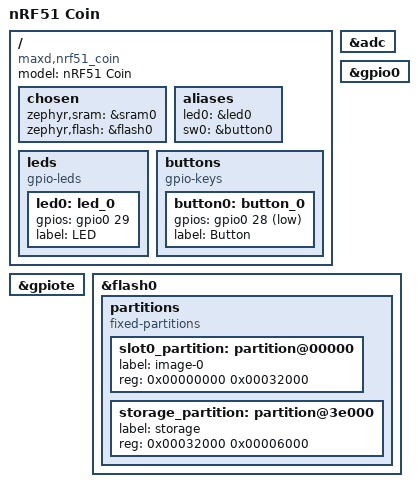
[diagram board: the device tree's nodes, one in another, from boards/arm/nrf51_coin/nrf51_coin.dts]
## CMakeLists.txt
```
cmake_minimum_required(VERSION 3.8.2)

get_filename_component( ENV{ZEPHYR_BASE} "${CMAKE_SOURCE_DIR}/../zephyr" ABSOLUTE)
set( ENV{BOARD} nrf51_coin )
set( BOARD_ROOT ${CMAKE_SOURCE_DIR} )
set( ENV{ZEPHYR_TOOLCHAIN_VARIANT} zephyr )
set( ENV{ZEPHYR_SDK_INSTALL_DIR} /opt/zephyr-sdk/ )

include($ENV{ZEPHYR_BASE}/cmake/app/boilerplate.cmake NO_POLICY_SCOPE)

project(coin)
zephyr_include_directories(
  $ENV{ZEPHYR_BASE}/subsys/bluetooth/host
  ../BLAKE2/ref
)


target_sources(app PRIVATE src/main.c src/bas.c src/io.c src/spaceauth.c ../BLAKE2/ref/blake2s-ref.c)
```

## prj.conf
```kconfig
CONFIG_BT=y
CONFIG_BT_SMP=y
CONFIG_BT_PERIPHERAL=y

CONFIG_BT_PRIVACY=y

CONFIG_BT_SMP_SC_ONLY=y
CONFIG_BT_MAX_CONN=1
CONFIG_BT_MAX_PAIRED=1

CONFIG_BT_SETTINGS=y
CONFIG_BT_BONDABLE=n
CONFIG_BT_DEVICE_NAME="Space"
CONFIG_BT_DEVICE_APPEARANCE=576
CONFIG_FLASH=y
CONFIG_FLASH_PAGE_LAYOUT=y
CONFIG_FLASH_MAP=y
CONFIG_FCB=y
CONFIG_SETTINGS=y
CONFIG_SETTINGS_FCB=y

CONFIG_SYS_POWER_MANAGEMENT=y
CONFIG_SYS_POWER_DEEP_SLEEP_STATES=y
CONFIG_DEVICE_POWER_MANAGEMENT=y
CONFIG_ADC=y
CONFIG_ADC_0=y

CONFIG_BT_LL_SW_LEGACY=y

# "advanced settings"
#CONFIG_BT_HCI_TX_STACK_SIZE=640
#CONFIG_BT_HCI_ECC_STACK_SIZE=1100
#CONFIG_BT_RX_STACK_SIZE=2200
#CONFIG_BT_CTLR_RX_PRIO_STACK_SIZE=448
#CONFIG_ISR_STACK_SIZE=640
CONFIG_MAIN_STACK_SIZE=512
#CONFIG_IDLE_STACK_SIZE=256
CONFIG_SYSTEM_WORKQUEUE_STACK_SIZE=512
CONFIG_OFFLOAD_WORKQUEUE_STACK_SIZE=512
CONFIG_BT_HCI_VS=n
CONFIG_BT_ASSERT=n
CONFIG_BT_RX_BUF_COUNT=2
CONFIG_BT_CONN_TX_MAX=1
CONFIG_BT_DISCARDABLE_BUF_COUNT=1
CONFIG_BT_L2CAP_TX_BUF_COUNT=2
#CONFIG_BT_ATT_TX_MAX=1
CONFIG_BT_GATT_READ_MULTIPLE=n
#CONFIG_BT_GAP_PERIPHERAL_PREF_PARAMS=n
#CONFIG_BT_CTLR_TX_BUFFERS=1
```

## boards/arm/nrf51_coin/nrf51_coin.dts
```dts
/*
 * Copyright (c) Maximilian Deubel
 *
 * SPDX-License-Identifier: Apache-2.0
 */

/dts-v1/;
#include <nordic/nrf51822_qfaa.dtsi>

/ {
	model = "nRF51 Coin";
	compatible = "maxd,nrf51_coin", "nordic,nrf51822-qfaa",
		     "nordic,nrf51822";

	chosen {
		zephyr,sram = &sram0;
		zephyr,flash = &flash0;
	};

	aliases {
		led0 = &led0;
		sw0 = &button0;
	};

	leds {
		compatible = "gpio-leds";
		led0: led_0 {
			gpios = <&gpio0 29 0>;
			label = "LED";
		};
	};

	buttons {
		compatible = "gpio-keys";
		button0: button_0 {
			gpios = <&gpio0 28 (GPIO_PUD_PULL_UP |
					    GPIO_INT_ACTIVE_LOW)>;
			label = "Button";
		};
	};
};

&adc {
	status ="okay";
};

&gpiote {
	status ="okay";
};

&gpio0 {
	status ="okay";
};

&flash0 {
	/*
	 * For more information, see:
	 * http://docs.zephyrproject.org/latest/guides/dts/index.html#flash-partitions
	 */
	partitions {
		compatible = "fixed-partitions";
		#address-cells = <1>;
		#size-cells = <1>;

		slot0_partition: partition@00000 {
			label = "image-0";
			reg = <0x00000000 0x00032000>;
		};
		storage_partition: partition@3e000 {
			label = "storage";
			reg = <0x00032000 0x00006000>;
		};
		/*
		 * REMEMBER TO UPDATE ADDRESS AND LENGTH IN prod/gen_bond.py
		 */
	};
};
```

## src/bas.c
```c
#include <zephyr.h>

uint8_t bas_init() {
	return 0;
}
```

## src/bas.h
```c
#pragma once

#ifdef __cplusplus
extern "C" {
#endif

/**
 * Initialize Battery Service.
 * This implementation directly uses the ADC with the on-board resistor divider to measure battery level.
 * @return initially measured battery level
 */
uint8_t bas_init();

#ifdef __cplusplus
}
#endif
```

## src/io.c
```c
#include "io.h"
#include <gpio.h>
#include <power.h>

#include <logging/log.h>

LOG_MODULE_REGISTER(io);

#define LED_PORT DT_ALIAS_LED0_GPIOS_CONTROLLER
#define LED DT_ALIAS_LED0_GPIOS_PIN
#define BTN DT_ALIAS_SW0_GPIOS_PIN

static struct gpio_callback btn_cb = {{0}};

static struct device *dev = NULL;

struct k_timer blink_timer = {{{{0}}}};

static const int aggressive_blink_ms = 125;
static const int quick_blink_ms = 250;
static const int slow_blink_ms = 500;

static const uint16_t sos_sequence[] = {250, 125, 250, 125, 250, 125,
                                        500, 125, 500, 125, 500, 125,
                                        250, 125, 250, 125, 250, 1000,
                                        250, 125, 250, 125, 250, 125,
                                        500, 125, 500, 125, 500, 125,
                                        250, 125, 250, 125, 250, 125};
static int sos_index = -1;

void set_blink_intensity(blink_state_t intensity) {
    if (sos_index > -1) {
        return;
    }
    switch (intensity) {
        case BI_ON:
            LOG_INF("turn LED on");
            k_timer_stop(&blink_timer);
            gpio_pin_write(dev, LED, 1);
            break;
        case BI_AGGRESSIVE:
            LOG_INF("aggressive LED blink");
            k_timer_start(&blink_timer, K_MSEC(aggressive_blink_ms), K_MSEC(aggressive_blink_ms));
            break;
        case BI_QUICK:
            LOG_INF("quick LED blink");
            k_timer_start(&blink_timer, K_MSEC(quick_blink_ms), K_MSEC(quick_blink_ms));
            break;
        case BI_SLOW:
            LOG_INF("slow LED blink");
            k_timer_start(&blink_timer, K_MSEC(slow_blink_ms), K_MSEC(slow_blink_ms));
            break;
        case BI_SOS:
            LOG_INF("distress signal");
            gpio_pin_write(dev, LED, 1);
            sos_index = 0;
            k_timer_start(&blink_timer, K_MSEC(sos_sequence[0]), 0);
            break;
        default:
        case BI_OFF:
            LOG_INF("turn LED off");
            k_timer_stop(&blink_timer);
            gpio_pin_write(dev, LED, 0);
            break;
    }
}

static int blink_counter = 0;

static void blink_expiry_function(struct k_timer *timer_id) {
    ARG_UNUSED(timer_id);
    if (sos_index > -1) { //SOS mode
        sos_index += 1;
        if (sos_index < ARRAY_SIZE(sos_sequence)) {
            gpio_pin_write(dev, LED, 1 - (sos_index % 2));
            k_timer_start(&blink_timer, K_MSEC(sos_sequence[sos_index]), 0);
        } else {
            gpio_pin_write(dev, LED, 0);
            sys_pm_force_power_state(SYS_POWER_STATE_DEEP_SLEEP_1);
        }
    } else {
        gpio_pin_write(dev, LED, (blink_counter++) % 2);
    }
}

static void button_pressed(struct device *btn_dev, struct gpio_callback *cb, u32_t pins) {
    ARG_UNUSED(btn_dev);
    ARG_UNUSED(cb);
    ARG_UNUSED(pins);
    //LOG_INF("button pressed");
}

void io_init() {
    LOG_INF("initialize LED and button");
    dev = device_get_binding(LED_PORT);

    gpio_pin_configure(dev, LED, GPIO_DIR_OUT);
    gpio_pin_configure(dev, BTN,
                       GPIO_DIR_IN | GPIO_PUD_PULL_UP | GPIO_INT_LEVEL |
                       GPIO_INT | GPIO_INT_ACTIVE_LOW);
    gpio_init_callback(&btn_cb, button_pressed, BIT(BTN));
    gpio_add_callback(dev, &btn_cb);
    gpio_pin_enable_callback(dev, BTN);

    k_timer_init(&blink_timer, blink_expiry_function, NULL);
    set_blink_intensity(BI_ON);
}
```

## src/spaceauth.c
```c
#include <zephyr.h>
#include <settings/settings.h>
#include <bluetooth/gatt.h>

#include "blake2.h"
#include "spaceauth.h"

#include <logging/log.h>

LOG_MODULE_REGISTER(spaceauth);


static struct bt_uuid_128 auth_service_uuid = BT_UUID_INIT_128(
        0xee, 0x8a, 0xcb, 0x07, 0x8d, 0xe1, 0xfc, 0x3b,
        0xfe, 0x8e, 0x69, 0x22, 0x41, 0xbe, 0x87, 0x66);

static struct bt_uuid_128 auth_challenge_uuid = BT_UUID_INIT_128(
        0xd5, 0x12, 0x7b, 0x77, 0xce, 0xba, 0xa7, 0xb1,
        0x86, 0x9a, 0x90, 0x47, 0x02, 0xc9, 0x3d, 0x95);

static struct bt_uuid_128 auth_response_uuid = BT_UUID_INIT_128(
        0x06, 0x3f, 0x0b, 0x51, 0xbf, 0x48, 0x4f, 0x95,
        0x92, 0xd7, 0x28, 0x5c, 0xd6, 0xfd, 0xd2, 0x2f);

static uint8_t auth_key[BLAKE2S_KEYBYTES] = {0};
static uint8_t challenge[BLAKE2S_BLOCKBYTES] = {0};
static uint8_t response[BLAKE2S_OUTBYTES] = {0};

static u16_t ccc_value;

static void ccc_cfg_changed(const struct bt_gatt_attr *attr, u16_t value) {
    ARG_UNUSED(attr);
    ccc_value = value;
}

static void indicate_cb(struct bt_conn *conn, const struct bt_gatt_attr *attr,
                        u8_t err) {
    ARG_UNUSED(attr);
    ARG_UNUSED(conn);
    if (err != 0U) {
        LOG_ERR("indication fail: %i", err);
    } else {
        LOG_INF("indication success");
    }
}

static struct bt_gatt_indicate_params ind_params = {.data=response, .len=BLAKE2S_OUTBYTES, .attr=NULL, .func=&indicate_cb};

static ssize_t write_challenge(struct bt_conn *conn,
                               const struct bt_gatt_attr *attr,
                               const void *buf, u16_t len,
                               u16_t offset, u8_t flags);

static ssize_t read_response(struct bt_conn *conn,
                             const struct bt_gatt_attr *attr,
                             void *buf, u16_t len,
                             u16_t offset) {
    const char *value = attr->user_data;

    return bt_gatt_attr_read(conn, attr, buf, len, offset, value,
                             BLAKE2S_OUTBYTES);
}

BT_GATT_SERVICE_DEFINE(auth_svc,
                       BT_GATT_PRIMARY_SERVICE(&auth_service_uuid),
                       BT_GATT_CHARACTERISTIC(&auth_challenge_uuid.uuid, BT_GATT_CHRC_WRITE | BT_GATT_CHRC_AUTH,
                                              BT_GATT_PERM_WRITE_AUTHEN | BT_GATT_PERM_WRITE_ENCRYPT,
                                              NULL, write_challenge, challenge),
                       BT_GATT_CHARACTERISTIC(&auth_response_uuid.uuid, BT_GATT_CHRC_READ | BT_GATT_CHRC_INDICATE,
                                              BT_GATT_PERM_READ_AUTHEN | BT_GATT_PERM_READ_ENCRYPT,
                                              read_response, NULL, response),
                       BT_GATT_CCC(ccc_cfg_changed)
);

static const size_t INDICATION_PROTOCOL_OVERHEAD = 3;
static const size_t AUTH_RESPONSE_CHR_VALUE_HANDLE = 4;

static ssize_t write_challenge(struct bt_conn *conn,
                               const struct bt_gatt_attr *attr,
                               const void *buf, u16_t len,
                               u16_t offset, u8_t flags) {
    ARG_UNUSED(attr);
    ARG_UNUSED(flags);
    if (offset + len > BLAKE2S_BLOCKBYTES) {
        return BT_GATT_ERR(BT_ATT_ERR_INVALID_OFFSET);
    }

    memcpy(challenge + offset, buf, len);
    LOG_INF("write challenge offset: %i, len: %i", offset, len);

    if (offset + len == BLAKE2S_BLOCKBYTES) {
        blake2s(response, BLAKE2S_OUTBYTES, challenge, BLAKE2S_BLOCKBYTES, auth_key, BLAKE2S_KEYBYTES);
        if (ccc_value == BT_GATT_CCC_INDICATE) {
            ind_params.attr = &auth_svc.attrs[AUTH_RESPONSE_CHR_VALUE_HANDLE];
            u16_t mtu = bt_gatt_get_mtu(conn);
            ind_params.len = MIN(mtu - INDICATION_PROTOCOL_OVERHEAD, BLAKE2S_OUTBYTES);
            LOG_INF("connection has MTU: %u", mtu);
            bt_gatt_indicate(NULL, &ind_params);
        }
    }

    return len;
}

//settings stuff
static int set(const char *key, size_t len_rd,
               settings_read_cb read_cb, void *cb_arg) {
    ARG_UNUSED(len_rd);
    const char *next;

    size_t key_len = (size_t) settings_name_next(key, &next);
    if (!next) {
        if (!strncmp(key, "key", key_len)) {
            ssize_t len = read_cb(cb_arg, auth_key, BLAKE2S_KEYBYTES);
            if (len != BLAKE2S_KEYBYTES) {
                memset(auth_key, 0, BLAKE2S_KEYBYTES);
                return (len < 0) ? len : -EINVAL;
            }
            LOG_INF("loaded spacekey");
            return 0;
        }
    }
    return -ENOENT;
}

static struct settings_handler auth_settings = {
        .name = "space",
        .h_set = set,
};

void space_auth_init(void) {
    LOG_INF("initialize space auth");
    int err;

    err = settings_subsys_init();
    if (err) {
        LOG_ERR("settings_subsys_init failed (err %d)", err);
    }

    err = settings_register(&auth_settings);
    if (err) {
        LOG_ERR("ps_settings_register failed (err %d)", err);
    }
}
```
